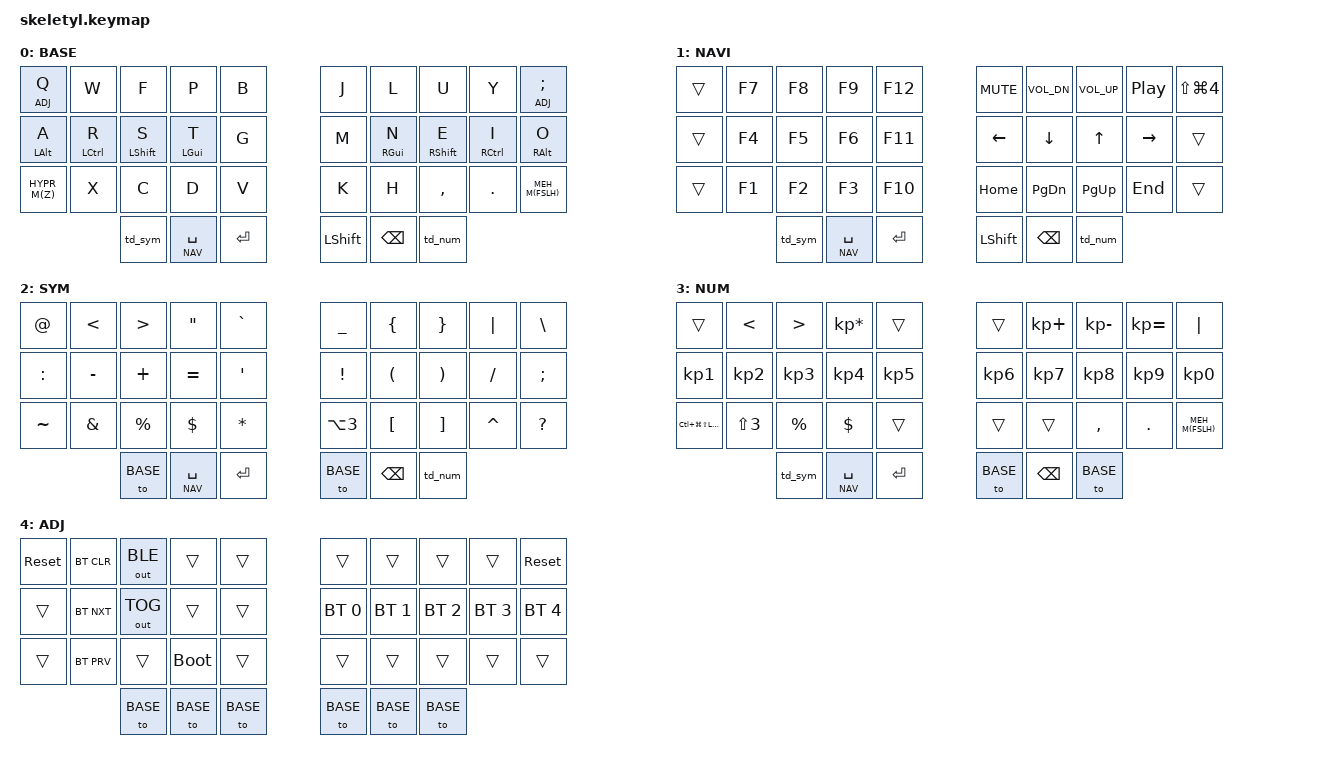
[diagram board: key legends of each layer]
/*
 * Copyright (c) 2023 Charly Delay <0xcharly>
 *
 * SPDX-License-Identifier: MIT
 */

#include <behaviors.dtsi>
#include <dt-bindings/zmk/bt.h>
#include <dt-bindings/zmk/ext_power.h>
#include <dt-bindings/zmk/keys.h>
#include <dt-bindings/zmk/rgb.h>
#include <dt-bindings/zmk/outputs.h>

#define BASE 0
#define NAV  1
#define SYM  2
#define NUM  3
#define ADJ  4

#define MO_SL(layer) &mo_sl layer layer
#define HYPR &kp LC(LG(LS(LALT))) 
#define MEH &kp LC(LS(LALT)) 

#define HYPR_M(kc) &hm LC(LG(LS(LALT))) kc
#define MEH_M(kc) &hm LC(LS(LALT)) kc


&mt {
    tapping-term-ms = <201>;
    flavor = "tap-preferred";
 };
&sk {
     release-after-ms = <2000>;
     quick-release;
 };

/ {
  // Conditional layers configuration, specifically tri-layer.

  macros {

  };

  /**
   * Combos configuration: only on base layer.
   *
   * Combo key positions:
   *
   *    0  1  2  3  4    5  6  7  8  9
   *   10 11 12 13 14    15 16 17 18 19
   *   20 21 22 23 24    25 26 27 28 29
   *         30 31 32    33 34 35
   */
  combos {
    compatible = "zmk,combos";
        combo_esc {
            timeout-ms = <30>;
            key-positions = <11 12>;
            bindings = <&kp ESC>; 
          };

        combo_tab {
            timeout-ms = <30>;
            key-positions = <17 18>;
            bindings = <&kp TAB>;
        };

  };

  behaviors {

    // Key positions:
    //
    //    0  1  2  3  4    5  6  7  8  9
    //   10 11 12 13 14    15 16 17 18 19
    //   20 21 22 23 24    25 26 27 28 29
    //         30 31 32    33 34 35

         td_num: num_layer_dance {
            compatible = "zmk,behavior-tap-dance";
            #binding-cells = <0>;
            tapping-term-ms = <200>;
            bindings = <&sl NUM>, <&to NUM>;
          };

         td_sym: sym_layer_dance {
            compatible = "zmk,behavior-tap-dance";
            #binding-cells = <0>;
            tapping-term-ms = <200>;
            bindings = <&sl SYM>, <&to SYM>;
          };
         hm: homerow_mods {
            compatible = "zmk,behavior-hold-tap";
            #binding-cells = <2>;
            tapping-term-ms = <300>;
            quick-tap-ms = <250>;
            flavor = "tap-preferred";
            bindings = <&kp>, <&kp>;
        };
         hm_l: homerow_mods_left {
            compatible = "zmk,behavior-hold-tap";
            #binding-cells = <2>;
            tapping-term-ms = <300>;
            quick-tap-ms = <250>;
            flavor = "tap-preferred";
            bindings = <&kp>, <&kp>;
            hold-trigger-key-positions = <5 6 7 8 9 15 16 17 18 19 25 26 27 28 29 33 34 35>; // Right-hand keys.
        };
        hm_r: homerow_mods_right {
            compatible = "zmk,behavior-hold-tap";
            #binding-cells = <2>;
            tapping-term-ms = <300>;
            quick-tap-ms = <250>;
            flavor = "tap-preferred";
            bindings = <&kp>, <&kp>;
            hold-trigger-key-positions = <0 1 2 3 4 10 11 12 13 14 20 21 22 23 24 30 31 32>; // Left-hand keys.
        };
        hl_l: homerow_layers_left {
            compatible = "zmk,behavior-hold-tap";
            #binding-cells = <2>;
            tapping-term-ms = <220>;
            quick-tap-ms = <250>;
            flavor = "tap-preferred";
            bindings = <&mo>, <&kp>;
        };
        hl_r: homerow_layers_right {
            compatible = "zmk,behavior-hold-tap";
            #binding-cells = <2>;
            tapping-term-ms = <220>;
            quick-tap-ms = <250>;
            flavor = "tap-preferred";
            bindings = <&mo>, <&kp>;
        };
    td: tapdance {
            compatible = "zmk,behavior-hold-tap";
            #binding-cells = <2>;
            tapping-term-ms = <190>;
            quick-tap-ms = <250>;
            flavor = "tap-preferred";
            bindings = <&kp>, <&kp>;
        };
  };

  /**
   * 36-key keymap, using a Dvorak base layer.
   */
  keymap {
    compatible = "zmk,keymap";


// ▄▄▄▄▄▄▄▄▄▄▄▄▄▄▄▄▄▄▄▄▄▄▄▄▄▄▄▄▄▄▄▄▄▄▄▄▄▄▄▄▄▄▄▄▄▄▄▄▄▄▄▄▄▄▄▄▄▄▄▄▄▄▄▄▄▄▄▄▄▄▄▄▄▄▄▄▄▄▄▄▄▄▄▄▄▄▄▄▄▄▄▄▄▄▄▄▄▄▄▄▄▄▄▄▄▄▄▄▄▄▄▄▄▄▄▄▄▄▄▄▄▄▄▄▄▄▄▄▄▄▄▄▄▄▄▄▄▄▄▄▄▄▄▄▄▄▄▄▄

                base_layer {
// ┏━━━━━━━━━━━━━━━━━━━━━━━━━━━━━━━━━━━━━━━┓
label= "BASE"                              ;
// ┗━━━━━━━━━━━━━━━━━━━━━━━━━━━━━━━━━━━━━━━┛
//             ┏━━━━━━━━━━━┳━━━━━━━━━━━┳━━━━━━━━━━━┳━━━━━━━━━━━┳━━━━━━━━━━━┓   ┏━━━━━━━━━━━┳━━━━━━━━━━━┳━━━━━━━━━━━┳━━━━━━━━━━━┳━━━━━━━━━━━┓
//             ┃     Q     ┃     W     ┃     F     ┃     P     ┃     B     ┃   ┃     J     ┃     L     ┃     U     ┃     Y     ┃     ;     ┃
//             ┣━━━━━━━━━━━╋━━━━━━━━━━━╋━━━━━━━━━━━╋━━━━━━━━━━━╋━━━━━━━━━━━┫   ┣━━━━━━━━━━━╋━━━━━━━━━━━╋━━━━━━━━━━━╋━━━━━━━━━━━╋━━━━━━━━━━━┫
//             ┃     A     ┃     R     ┃     S     ┃     T     ┃     G     ┃   ┃     M     ┃     N     ┃     E     ┃     I     ┃     O     ┃
//             ┣━━━━━━━━━━━╋━━━━━━━━━━━╋━━━━━━━━━━━╋━━━━━━━━━━━╋━━━━━━━━━━━┫   ┣━━━━━━━━━━━╋━━━━━━━━━━━╋━━━━━━━━━━━╋━━━━━━━━━━━╋━━━━━━━━━━━┫
//             ┃     Z     ┃     X     ┃     C     ┃     D     ┃     V     ┃   ┃     K     ┃     H     ┃     ,     ┃     .     ┃     /     ┃
//             ┗━━━━━━━━━━━┻━━━━━━━━━━━╋━━━━━━━━━━━╋━━━━━━━━━━━╋━━━━━━━━━━━┫   ┣━━━━━━━━━━━╋━━━━━━━━━━━╋━━━━━━━━━━━╋━━━━━━━━━━━┻━━━━━━━━━━━┛
//                                     ┃    SYM    ┃    SPC    ┃   ENTER   ┃   ┃   LSHFT   ┃    BSPC   ┃    NUM    ┃
//                                     ┗━━━━━━━━━━━┻━━━━━━━━━━━┻━━━━━━━━━━━┛   ┗━━━━━━━━━━━┻━━━━━━━━━━━┻━━━━━━━━━━━┛
 bindings = <
// ╷           ╷           ╷           ╷           ╷           ╷           ╷   ╷           ╷           ╷           ╷           ╷           ╷           ╷

                &lt ADJ Q     &kp W          &kp F         &kp P        &kp B           &kp J       &kp L        &kp U         &kp Y          &lt ADJ SEMI
                &hm_l LALT A  &hm_l LCTRL R  &hm_l LSHFT S &hm_l LGUI T &kp G           &kp M       &hm_r RGUI N &hm_r RSHFT E &hm_r RCTRL I  &hm_r RALT O
                HYPR_M(Z)     &kp X          &kp C         &kp D        &kp V           &kp K       &kp H        &kp COMMA     &kp DOT        MEH_M(FSLH)   
                                        &td_sym     &hl_l NAV SPACE   &kp RET     &kp LSHFT   &kp BSPC    &td_num
                        >;
                };

// ▄▄▄▄▄▄▄▄▄▄▄▄▄▄▄▄▄▄▄▄▄▄▄▄▄▄▄▄▄▄▄▄▄▄▄▄▄▄▄▄▄▄▄▄▄▄▄▄▄▄▄▄▄▄▄▄▄▄▄▄▄▄▄▄▄▄▄▄▄▄▄▄▄▄▄▄▄▄▄▄▄▄▄▄▄▄▄▄▄▄▄▄▄▄▄▄▄▄▄▄▄▄▄▄▄▄▄▄▄▄▄▄▄▄▄▄▄▄▄▄▄▄▄▄▄▄▄▄▄▄▄▄▄▄▄▄▄▄▄▄▄▄▄▄▄▄▄▄▄


                nav_layer {
// ┏━━━━━━━━━━━━━━━━━━━━━━━━━━━━━━━━━━━━━━━┓
label= "NAVI"                              ;
// ┗━━━━━━━━━━━━━━━━━━━━━━━━━━━━━━━━━━━━━━━┛
//             ┏━━━━━━━━━━━┳━━━━━━━━━━━┳━━━━━━━━━━━┳━━━━━━━━━━━┳━━━━━━━━━━━┓   ┏━━━━━━━━━━━┳━━━━━━━━━━━┳━━━━━━━━━━━┳━━━━━━━━━━━┳━━━━━━━━━━━┓
//             ┃           ┃    F7     ┃     F8    ┃    F9     ┃    F12    ┃   ┃   MUTE    ┃  V DOWN   ┃    V UP   ┃   PLAY    ┃   SCNSHT  ┃
//             ┣━━━━━━━━━━━╋━━━━━━━━━━━╋━━━━━━━━━━━╋━━━━━━━━━━━╋━━━━━━━━━━━┫   ┣━━━━━━━━━━━╋━━━━━━━━━━━╋━━━━━━━━━━━╋━━━━━━━━━━━╋━━━━━━━━━━━┫
//             ┃           ┃    F4     ┃     F5    ┃    F6     ┃    F11    ┃   ┃   LEFT    ┃   DOWN    ┃     UP    ┃   RIGHT   ┃           ┃
//             ┣━━━━━━━━━━━╋━━━━━━━━━━━╋━━━━━━━━━━━╋━━━━━━━━━━━╋━━━━━━━━━━━┫   ┣━━━━━━━━━━━╋━━━━━━━━━━━╋━━━━━━━━━━━╋━━━━━━━━━━━╋━━━━━━━━━━━┫
//             ┃           ┃    F1     ┃     F2    ┃    F3     ┃    F10    ┃   ┃   HOME    ┃  P DOWN   ┃    P UP   ┃    END    ┃           ┃
//             ┗━━━━━━━━━━━┻━━━━━━━━━━━╋━━━━━━━━━━━╋━━━━━━━━━━━╋━━━━━━━━━━━┫   ┣━━━━━━━━━━━╋━━━━━━━━━━━╋━━━━━━━━━━━╋━━━━━━━━━━━┻━━━━━━━━━━━┛
//                                     ┃    SYM    ┃           ┃   ENTER   ┃   ┃   LSHFT   ┃    BSPC   ┃    NUM    ┃
//                                     ┗━━━━━━━━━━━┻━━━━━━━━━━━┻━━━━━━━━━━━┛   ┗━━━━━━━━━━━┻━━━━━━━━━━━┻━━━━━━━━━━━┛
 bindings = <
// ╷           ╷           ╷           ╷           ╷           ╷           ╷   ╷           ╷           ╷           ╷           ╷           ╷           ╷

                &trans      &kp F7      &kp F8      &kp F9      &kp F12         &kp C_MUTE  &kp C_VOL_DN   &kp C_VOL_UP   &kp C_PP    &kp LS(LG(NUMBER_4))
                &trans      &kp F4      &kp F5      &kp F6      &kp F11         &kp LEFT    &kp DOWN       &kp UP         &kp RIGHT   &trans
                &trans      &kp F1      &kp F2      &kp F3      &kp F10         &kp HOME    &kp PG_DN      &kp PG_UP      &kp END     &trans    
                                        &td_sym     &hl_l NAV SPACE   &kp RET     &kp LSHFT   &kp BSPC    &td_num
                        >;
                };

// ▄▄▄▄▄▄▄▄▄▄▄▄▄▄▄▄▄▄▄▄▄▄▄▄▄▄▄▄▄▄▄▄▄▄▄▄▄▄▄▄▄▄▄▄▄▄▄▄▄▄▄▄▄▄▄▄▄▄▄▄▄▄▄▄▄▄▄▄▄▄▄▄▄▄▄▄▄▄▄▄▄▄▄▄▄▄▄▄▄▄▄▄▄▄▄▄▄▄▄▄▄▄▄▄▄▄▄▄▄▄▄▄▄▄▄▄▄▄▄▄▄▄▄▄▄▄▄▄▄▄▄▄▄▄▄▄▄▄▄▄▄▄▄▄▄▄▄▄▄


                sym_layer {
// ┏━━━━━━━━━━━━━━━━━━━━━━━━━━━━━━━━━━━━━━━┓
label= "SYM"                               ;
// ┗━━━━━━━━━━━━━━━━━━━━━━━━━━━━━━━━━━━━━━━┛
//             ┏━━━━━━━━━━━┳━━━━━━━━━━━┳━━━━━━━━━━━┳━━━━━━━━━━━┳━━━━━━━━━━━┓   ┏━━━━━━━━━━━┳━━━━━━━━━━━┳━━━━━━━━━━━┳━━━━━━━━━━━┳━━━━━━━━━━━┓
//             ┃     @     ┃     <     ┃     >     ┃     "     ┃     `     ┃   ┃     _     ┃     {     ┃     }     ┃     |     ┃     \     ┃
//             ┣━━━━━━━━━━━╋━━━━━━━━━━━╋━━━━━━━━━━━╋━━━━━━━━━━━╋━━━━━━━━━━━┫   ┣━━━━━━━━━━━╋━━━━━━━━━━━╋━━━━━━━━━━━╋━━━━━━━━━━━╋━━━━━━━━━━━┫
//             ┃     :     ┃     -     ┃     +     ┃     =     ┃     '     ┃   ┃     !     ┃     (     ┃     )     ┃     /     ┃     ;     ┃
//             ┣━━━━━━━━━━━╋━━━━━━━━━━━╋━━━━━━━━━━━╋━━━━━━━━━━━╋━━━━━━━━━━━┫   ┣━━━━━━━━━━━╋━━━━━━━━━━━╋━━━━━━━━━━━╋━━━━━━━━━━━╋━━━━━━━━━━━┫
//             ┃     ~     ┃     &     ┃     %     ┃     $     ┃     *     ┃   ┃     #     ┃     [     ┃     ]     ┃     ^     ┃     ?     ┃
//             ┗━━━━━━━━━━━┻━━━━━━━━━━━╋━━━━━━━━━━━╋━━━━━━━━━━━╋━━━━━━━━━━━┫   ┣━━━━━━━━━━━╋━━━━━━━━━━━╋━━━━━━━━━━━╋━━━━━━━━━━━┻━━━━━━━━━━━┛
//                                     ┃    BASE   ┃    SPC    ┃   ENTER   ┃   ┃    BASE   ┃    BSPC   ┃    NUM    ┃
//                                     ┗━━━━━━━━━━━┻━━━━━━━━━━━┻━━━━━━━━━━━┛   ┗━━━━━━━━━━━┻━━━━━━━━━━━┻━━━━━━━━━━━┛
 bindings = <
// ╷           ╷           ╷           ╷           ╷           ╷           ╷   ╷           ╷           ╷           ╷           ╷           ╷           ╷

                &kp AT      &kp LT      &kp GT      &kp DQT     &kp GRAVE       &kp UNDER        &kp LBRC    &kp RBRC    &kp PIPE    &kp BSLH       
                &kp COLON   &kp MINUS   &kp PLUS    &kp EQUAL   &kp SQT         &kp EXCL         &kp LPAR    &kp RPAR    &kp FSLH    &kp SEMI       
                &kp TILDE   &kp AMPS    &kp PRCNT   &kp DLLR    &kp STAR        &kp LA(NUMBER_3) &kp LBKT    &kp RBKT    &kp CARET   &kp QMARK   
                                        &to BASE    &hl_l NAV SPACE   &kp RET     &to BASE   &kp BSPC    &td_num
                        >;
                };

// ▄▄▄▄▄▄▄▄▄▄▄▄▄▄▄▄▄▄▄▄▄▄▄▄▄▄▄▄▄▄▄▄▄▄▄▄▄▄▄▄▄▄▄▄▄▄▄▄▄▄▄▄▄▄▄▄▄▄▄▄▄▄▄▄▄▄▄▄▄▄▄▄▄▄▄▄▄▄▄▄▄▄▄▄▄▄▄▄▄▄▄▄▄▄▄▄▄▄▄▄▄▄▄▄▄▄▄▄▄▄▄▄▄▄▄▄▄▄▄▄▄▄▄▄▄▄▄▄▄▄▄▄▄▄▄▄▄▄▄▄▄▄▄▄▄▄▄▄▄

                num_layer {
// ┏━━━━━━━━━━━━━━━━━━━━━━━━━━━━━━━━━━━━━━━┓
label= "NUM"                               ;
// ┗━━━━━━━━━━━━━━━━━━━━━━━━━━━━━━━━━━━━━━━┛
//             ┏━━━━━━━━━━━┳━━━━━━━━━━━┳━━━━━━━━━━━┳━━━━━━━━━━━┳━━━━━━━━━━━┓   ┏━━━━━━━━━━━┳━━━━━━━━━━━┳━━━━━━━━━━━┳━━━━━━━━━━━┳━━━━━━━━━━━┓
//             ┃           ┃     <     ┃     >     ┃     *     ┃           ┃   ┃           ┃     +     ┃     -     ┃     =     ┃     |     ┃
//             ┣━━━━━━━━━━━╋━━━━━━━━━━━╋━━━━━━━━━━━╋━━━━━━━━━━━╋━━━━━━━━━━━┫   ┣━━━━━━━━━━━╋━━━━━━━━━━━╋━━━━━━━━━━━╋━━━━━━━━━━━╋━━━━━━━━━━━┫
//             ┃     1     ┃     2     ┃     3     ┃     4     ┃     5     ┃   ┃     6     ┃     7     ┃     8     ┃     9     ┃     0     ┃
//             ┣━━━━━━━━━━━╋━━━━━━━━━━━╋━━━━━━━━━━━╋━━━━━━━━━━━╋━━━━━━━━━━━┫   ┣━━━━━━━━━━━╋━━━━━━━━━━━╋━━━━━━━━━━━╋━━━━━━━━━━━╋━━━━━━━━━━━┫
//             ┃           ┃     £     ┃     %     ┃     $     ┃           ┃   ┃           ┃           ┃     ,     ┃     .     ┃     /     ┃
//             ┗━━━━━━━━━━━┻━━━━━━━━━━━╋━━━━━━━━━━━╋━━━━━━━━━━━╋━━━━━━━━━━━┫   ┣━━━━━━━━━━━╋━━━━━━━━━━━╋━━━━━━━━━━━╋━━━━━━━━━━━┻━━━━━━━━━━━┛
//                                     ┃    SYM    ┃    SPC    ┃   ENTER   ┃   ┃    BASE   ┃    BSPC   ┃    BASE   ┃
//                                     ┗━━━━━━━━━━━┻━━━━━━━━━━━┻━━━━━━━━━━━┛   ┗━━━━━━━━━━━┻━━━━━━━━━━━┻━━━━━━━━━━━┛
 bindings = <
// ╷           ╷           ╷           ╷           ╷           ╷           ╷   ╷           ╷           ╷           ╷           ╷           ╷           ╷

                &trans     &kp LT            &kp GT            &kp KP_MULTIPLY   &trans               &trans      &kp KP_PLUS   &kp KP_MINUS  &kp KP_EQUAL  &kp PIPE      
                &kp KP_N1  &kp KP_N2         &kp KP_N3         &kp KP_N4         &kp KP_N5            &kp KP_N6   &kp KP_N7     &kp KP_N8     &kp KP_N9     &kp KP_N0
                HYPR       &kp LS(NUMBER_3)  &kp PRCNT         &kp DLLR          &trans               &trans      &trans        &kp COMMA     &kp DOT       MEH_M(FSLH)      
                                             &td_sym           &hl_l NAV SPACE     &kp RET              &to BASE    &kp BSPC      &to BASE
                        >;
                };

// ▄▄▄▄▄▄▄▄▄▄▄▄▄▄▄▄▄▄▄▄▄▄▄▄▄▄▄▄▄▄▄▄▄▄▄▄▄▄▄▄▄▄▄▄▄▄▄▄▄▄▄▄▄▄▄▄▄▄▄▄▄▄▄▄▄▄▄▄▄▄▄▄▄▄▄▄▄▄▄▄▄▄▄▄▄▄▄▄▄▄▄▄▄▄▄▄▄▄▄▄▄▄▄▄▄▄▄▄▄▄▄▄▄▄▄▄▄▄▄▄▄▄▄▄▄▄▄▄▄▄▄▄▄▄▄▄▄▄▄▄▄▄▄▄▄▄▄▄▄



                adjust_layer {
// ┏━━━━━━━━━━━━━━━━━━━━━━━━━━━━━━━━━━━━━━━┓
label= "ADJ"                               ;
// ┗━━━━━━━━━━━━━━━━━━━━━━━━━━━━━━━━━━━━━━━┛
//             ┏━━━━━━━━━━━┳━━━━━━━━━━━┳━━━━━━━━━━━┳━━━━━━━━━━━┳━━━━━━━━━━━┓   ┏━━━━━━━━━━━┳━━━━━━━━━━━┳━━━━━━━━━━━┳━━━━━━━━━━━┳━━━━━━━━━━━┓
//             ┃   RESET   ┃ BT CLEAR  ┃  OUT BLE  ┃           ┃           ┃   ┃           ┃           ┃           ┃           ┃   RESET   ┃
//             ┣━━━━━━━━━━━╋━━━━━━━━━━━╋━━━━━━━━━━━╋━━━━━━━━━━━╋━━━━━━━━━━━┫   ┣━━━━━━━━━━━╋━━━━━━━━━━━╋━━━━━━━━━━━╋━━━━━━━━━━━╋━━━━━━━━━━━┫
//             ┃           ┃ BT NEXT   ┃  OUT TOG  ┃           ┃           ┃   ┃    BT 1   ┃    BT 2   ┃   BT 3    ┃    BT 4   ┃   BT 5    ┃
//             ┣━━━━━━━━━━━╋━━━━━━━━━━━╋━━━━━━━━━━━╋━━━━━━━━━━━╋━━━━━━━━━━━┫   ┣━━━━━━━━━━━╋━━━━━━━━━━━╋━━━━━━━━━━━╋━━━━━━━━━━━╋━━━━━━━━━━━┫
//             ┃           ┃ BT PREV   ┃           ┃  BOOTLOAD ┃           ┃   ┃           ┃           ┃           ┃           ┃           ┃           
//             ┗━━━━━━━━━━━┻━━━━━━━━━━━╋━━━━━━━━━━━╋━━━━━━━━━━━╋━━━━━━━━━━━┫   ┣━━━━━━━━━━━╋━━━━━━━━━━━╋━━━━━━━━━━━╋━━━━━━━━━━━┻━━━━━━━━━━━┛
//                                     ┃           ┃           ┃           ┃   ┃           ┃           ┃           ┃
//                                     ┗━━━━━━━━━━━┻━━━━━━━━━━━┻━━━━━━━━━━━┛   ┗━━━━━━━━━━━┻━━━━━━━━━━━┻━━━━━━━━━━━┛
 bindings = <
// ╷           ╷           ╷           ╷           ╷           ╷           ╷   ╷           ╷           ╷           ╷           ╷           ╷           ╷

                &sys_reset  &bt BT_CLR  &out OUT_BLE    &trans      &trans          &trans          &trans        &trans          &trans          &sys_reset
                &trans      &bt BT_NXT  &out OUT_TOG    &trans      &trans          &bt BT_SEL 0    &bt BT_SEL 1  &bt BT_SEL 2    &bt BT_SEL 3    &bt BT_SEL 4 
                &trans      &bt BT_PRV  &trans          &bootloader &trans          &trans          &trans        &trans          &trans          &trans              
                                        &to BASE      &to BASE      &to BASE        &to BASE      &to BASE      &to BASE      
                        >;
    };
  };
};
